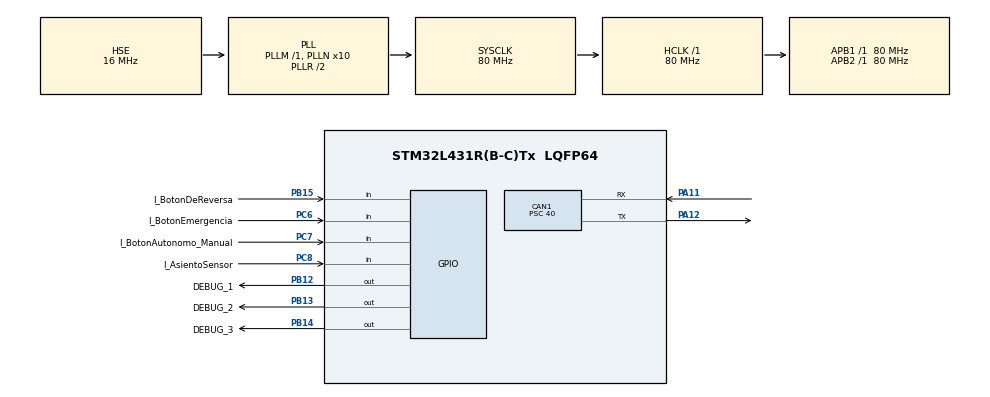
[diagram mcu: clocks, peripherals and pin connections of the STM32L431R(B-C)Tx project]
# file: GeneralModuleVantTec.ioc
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CAN1.BS1=CAN_BS1_13TQ
CAN1.BS2=CAN_BS2_2TQ
CAN1.CalculateBaudRate=125000
CAN1.CalculateTimeBit=8000
CAN1.CalculateTimeQuantum=500.0
CAN1.Prescaler=40
FREERTOS.Tasks01=defaultTask,24,128,StartDefaultTask,Default,NULL,Dynamic,NULL,NULL
FREERTOS.configTOTAL_HEAP_SIZE=10000
FREERTOS.configUSE_NEWLIB_REENTRANT=1
Mcu.Family=STM32L4
Mcu.Name=STM32L431R(B-C)Tx
Mcu.Package=LQFP64
NVIC.PriorityGroup=NVIC_PRIORITYGROUP_4
NVIC.TIM6_DAC_IRQn=true\:15\:0\:false\:false\:true\:false\:false\:true\:true
NVIC.TimeBase=TIM6_DAC_IRQn
NVIC.TimeBaseIP=TIM6
PA10.Signal=USART1_RX
PA11.Mode=CAN_Activate
PA11.Signal=CAN1_RX
PA12.Mode=CAN_Activate
PA12.Signal=CAN1_TX
PA13\ (JTMS-SWDIO).Mode=Trace_Asynchronous_SW
PA13\ (JTMS-SWDIO).Signal=SYS_JTMS-SWDIO
PA14\ (JTCK-SWCLK).Mode=Trace_Asynchronous_SW
PA14\ (JTCK-SWCLK).Signal=SYS_JTCK-SWCLK
PA9.Signal=USART1_TX
PB12.GPIO_Label=DEBUG_1
PB12.Signal=GPIO_Output
PB13.GPIO_Label=DEBUG_2
PB13.Signal=GPIO_Output
PB14.GPIO_Label=DEBUG_3
PB14.Signal=GPIO_Output
PB15.GPIO_Label=I_BotonDeReversa
PB15.Signal=GPIO_Input
PB3\ (JTDO-TRACESWO).Mode=Trace_Asynchronous_SW
PB3\ (JTDO-TRACESWO).Signal=SYS_JTDO-SWO
PC6.GPIO_Label=I_BotonEmergencia
PC6.Signal=GPIO_Input
PC7.GPIO_Label=I_BotonAutonomo_Manual
PC7.Signal=GPIO_Input
PC8.GPIO_Label=I_AsientoSensor
PC8.Signal=GPIO_Input
PH0-OSC_IN\ (PH0).Mode=HSE-External-Oscillator
PH0-OSC_IN\ (PH0).Signal=RCC_OSC_IN
PH1-OSC_OUT\ (PH1).Mode=HSE-External-Oscillator
PH1-OSC_OUT\ (PH1).Signal=RCC_OSC_OUT
ProjectManager.HeapSize=0x200
ProjectManager.StackSize=0x400
ProjectManager.TargetToolchain=STM32CubeIDE
RCC.ADCFreq_Value=64000000
RCC.AHBFreq_Value=80000000
RCC.APB1Freq_Value=80000000
RCC.APB1TimFreq_Value=80000000
RCC.APB2Freq_Value=80000000
RCC.APB2TimFreq_Value=80000000
RCC.CortexFreq_Value=80000000
RCC.HCLKFreq_Value=80000000
RCC.HSE_VALUE=16000000
RCC.HSI48_VALUE=48000000
RCC.HSI_VALUE=16000000
RCC.LSE_VALUE=32768
RCC.MSI_VALUE=4000000
RCC.PLLN=10
RCC.PLLSourceVirtual=RCC_PLLSOURCE_HSE
RCC.SYSCLKFreq_VALUE=80000000
RCC.SYSCLKSource=RCC_SYSCLKSOURCE_PLLCLK
RCC.VCOOutputFreq_Value=160000000
VP_FREERTOS_VS_CMSIS_V2.Mode=CMSIS_V2
VP_SYS_VS_tim6.Mode=TIM6
board=custom

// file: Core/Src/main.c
/* USER CODE BEGIN Header */
/**
  ******************************************************************************
  * @file           : main.c
  * @brief          : Main program body
  ******************************************************************************
  * @attention
  *
  * Copyright (c) 2023 STMicroelectronics.
  * All rights reserved.
  *
  * This software is licensed under terms that can be found in the LICENSE file
  * in the root directory of this software component.
  * If no LICENSE file comes with this software, it is provided AS-IS.
  *
  ******************************************************************************
  */
/* USER CODE END Header */
#include "main.h"
#include "cmsis_os.h"

/* USER CODE BEGIN Includes */
#include "vanttec_canlib.h"
#include "vanttec_canlib_tx_task.h"
#include "vanttec_canlib_rx_task.h"
#include "general_tasks.h"
#include "requirements.h"
#include "vanttec_sdv_ids.h"

/* USER CODE END Includes */

CAN_HandleTypeDef hcan1;

/* Definitions for defaultTask */
osThreadId_t defaultTaskHandle;
const osThreadAttr_t defaultTask_attributes = {
  .name = "defaultTask",
  .stack_size = 128 * 4,
  .priority = (osPriority_t) osPriorityNormal,
};

void SystemClock_Config(void);
static void MX_GPIO_Init(void);
static void MX_CAN1_Init(void);
void StartDefaultTask(void *argument);

int main(void)
{

  /* MCU Configuration--------------------------------------------------------*/

  /* Reset of all peripherals, Initializes the Flash interface and the Systick. */
  HAL_Init();

  /* Configure the system clock */
  SystemClock_Config();

  /* Initialize all configured peripherals */
  MX_GPIO_Init();
  MX_CAN1_Init();
  /* USER CODE BEGIN 2 */
  int filters[] = {0x01A0, 0x0404, 0x0013};
  int filters_size = sizeof(filters) / sizeof(filters[0]);
  init_canlib(hcan1, VANTTEC_CAN_ID_GENERAL_TX, filters, filters_size);
  init_canlib_tx();
  init_canlib_rx();
  canlib_init_generic_tasks();

  //init_ping_task();
  init_requirements_task();
  init_general_task();

  /* USER CODE END 2 */

  /* Init scheduler */
  osKernelInitialize();

  /* Create the thread(s) */
  /* creation of defaultTask */
  defaultTaskHandle = osThreadNew(StartDefaultTask, NULL, &defaultTask_attributes);

  /* Start scheduler */
  osKernelStart();

  /* We should never get here as control is now taken by the scheduler */
  /* Infinite loop */
  while (1)
  {

  }
}

void SystemClock_Config(void)
{
  RCC_OscInitTypeDef RCC_OscInitStruct = {0};
  RCC_ClkInitTypeDef RCC_ClkInitStruct = {0};

  /** Configure the main internal regulator output voltage
  */
  if (HAL_PWREx_ControlVoltageScaling(PWR_REGULATOR_VOLTAGE_SCALE1) != HAL_OK)
  {
    Error_Handler();
  }

  /** Initializes the RCC Oscillators according to the specified parameters
  * in the RCC_OscInitTypeDef structure.
  */
  RCC_OscInitStruct.OscillatorType = RCC_OSCILLATORTYPE_HSE;
  RCC_OscInitStruct.HSEState = RCC_HSE_ON;
  RCC_OscInitStruct.PLL.PLLState = RCC_PLL_ON;
  RCC_OscInitStruct.PLL.PLLSource = RCC_PLLSOURCE_HSE;
  RCC_OscInitStruct.PLL.PLLM = 1;
  RCC_OscInitStruct.PLL.PLLN = 10;
  RCC_OscInitStruct.PLL.PLLP = RCC_PLLP_DIV7;
  RCC_OscInitStruct.PLL.PLLQ = RCC_PLLQ_DIV2;
  RCC_OscInitStruct.PLL.PLLR = RCC_PLLR_DIV2;
  if (HAL_RCC_OscConfig(&RCC_OscInitStruct) != HAL_OK)
  {
    Error_Handler();
  }

  /** Initializes the CPU, AHB and APB buses clocks
  */
  RCC_ClkInitStruct.ClockType = RCC_CLOCKTYPE_HCLK|RCC_CLOCKTYPE_SYSCLK
                              |RCC_CLOCKTYPE_PCLK1|RCC_CLOCKTYPE_PCLK2;
  RCC_ClkInitStruct.SYSCLKSource = RCC_SYSCLKSOURCE_PLLCLK;
  RCC_ClkInitStruct.AHBCLKDivider = RCC_SYSCLK_DIV1;
  RCC_ClkInitStruct.APB1CLKDivider = RCC_HCLK_DIV1;
  RCC_ClkInitStruct.APB2CLKDivider = RCC_HCLK_DIV1;

  if (HAL_RCC_ClockConfig(&RCC_ClkInitStruct, FLASH_LATENCY_4) != HAL_OK)
  {
    Error_Handler();
  }
}

static void MX_CAN1_Init(void)
{

  hcan1.Instance = CAN1;
  hcan1.Init.Prescaler = 40;
  hcan1.Init.Mode = CAN_MODE_NORMAL;
  hcan1.Init.SyncJumpWidth = CAN_SJW_1TQ;
  hcan1.Init.TimeSeg1 = CAN_BS1_13TQ;
  hcan1.Init.TimeSeg2 = CAN_BS2_2TQ;
  hcan1.Init.TimeTriggeredMode = DISABLE;
  hcan1.Init.AutoBusOff = DISABLE;
  hcan1.Init.AutoWakeUp = DISABLE;
  hcan1.Init.AutoRetransmission = DISABLE;
  hcan1.Init.ReceiveFifoLocked = DISABLE;
  hcan1.Init.TransmitFifoPriority = DISABLE;
  if (HAL_CAN_Init(&hcan1) != HAL_OK)
  {
    Error_Handler();
  }

}

static void MX_GPIO_Init(void)
{
  GPIO_InitTypeDef GPIO_InitStruct = {0};

  /* GPIO Ports Clock Enable */
  __HAL_RCC_GPIOH_CLK_ENABLE();
  __HAL_RCC_GPIOB_CLK_ENABLE();
  __HAL_RCC_GPIOC_CLK_ENABLE();
  __HAL_RCC_GPIOA_CLK_ENABLE();

  /*Configure GPIO pin Output Level */
  HAL_GPIO_WritePin(GPIOB, DEBUG_1_Pin|DEBUG_2_Pin|DEBUG_3_Pin, GPIO_PIN_RESET);

  /*Configure GPIO pins : DEBUG_1_Pin DEBUG_2_Pin DEBUG_3_Pin */
  GPIO_InitStruct.Pin = DEBUG_1_Pin|DEBUG_2_Pin|DEBUG_3_Pin;
  GPIO_InitStruct.Mode = GPIO_MODE_OUTPUT_PP;
  GPIO_InitStruct.Pull = GPIO_NOPULL;
  GPIO_InitStruct.Speed = GPIO_SPEED_FREQ_LOW;
  HAL_GPIO_Init(GPIOB, &GPIO_InitStruct);

  /*Configure GPIO pin : I_BotonDeReversa_Pin */
  GPIO_InitStruct.Pin = I_BotonDeReversa_Pin;
  GPIO_InitStruct.Mode = GPIO_MODE_INPUT;
  GPIO_InitStruct.Pull = GPIO_NOPULL;
  HAL_GPIO_Init(I_BotonDeReversa_GPIO_Port, &GPIO_InitStruct);

  /*Configure GPIO pins : I_BotonEmergencia_Pin I_BotonAutonomo_Manual_Pin I_AsientoSensor_Pin */
  GPIO_InitStruct.Pin = I_BotonEmergencia_Pin|I_BotonAutonomo_Manual_Pin|I_AsientoSensor_Pin;
  GPIO_InitStruct.Mode = GPIO_MODE_INPUT;
  GPIO_InitStruct.Pull = GPIO_NOPULL;
  HAL_GPIO_Init(GPIOC, &GPIO_InitStruct);

  /*Configure GPIO pins : PA9 PA10 */
  GPIO_InitStruct.Pin = GPIO_PIN_9|GPIO_PIN_10;
  GPIO_InitStruct.Mode = GPIO_MODE_AF_PP;
  GPIO_InitStruct.Pull = GPIO_NOPULL;
  GPIO_InitStruct.Speed = GPIO_SPEED_FREQ_VERY_HIGH;
  GPIO_InitStruct.Alternate = GPIO_AF7_USART1;
  HAL_GPIO_Init(GPIOA, &GPIO_InitStruct);

}

void StartDefaultTask(void *argument)
{
  for(;;)
  {
    osDelay(1);
  }
}

void HAL_TIM_PeriodElapsedCallback(TIM_HandleTypeDef *htim)
{
  if (htim->Instance == TIM6) {
    HAL_IncTick();
  }
}

void Error_Handler(void)
{
  __disable_irq();
  while (1)
  {
  }
}
